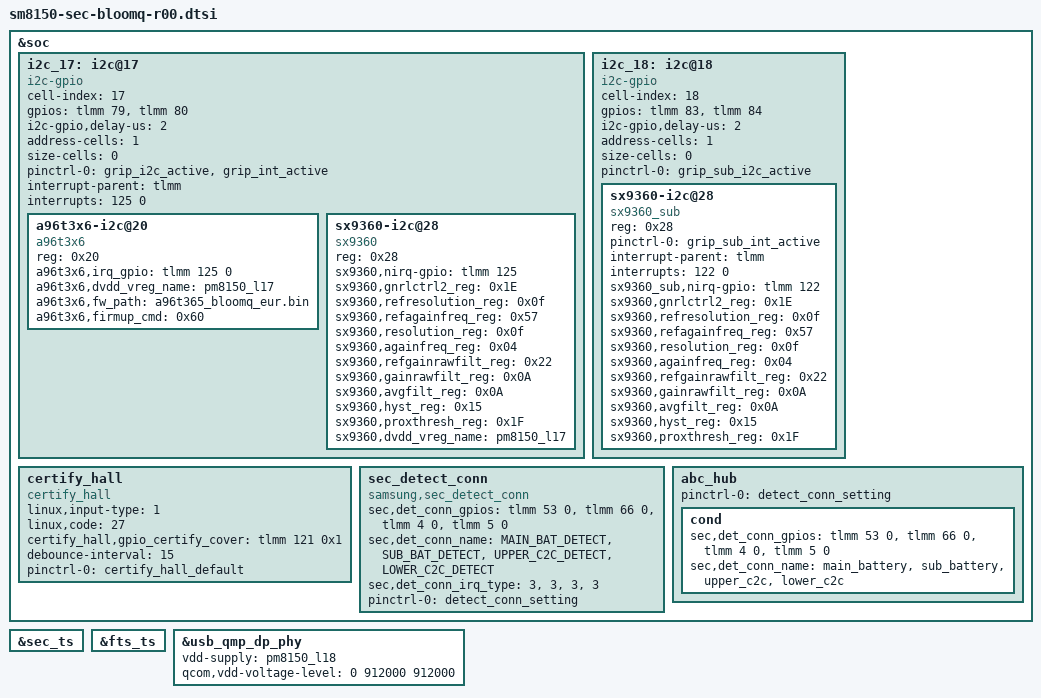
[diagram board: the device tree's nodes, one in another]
/* Copyright (c) 2016-2017, The Linux Foundation. All rights reserved.
 *
 * This program is free software; you can redistribute it and/or modify
 * it under the terms of the GNU General Public License version 2 and
 * only version 2 as published by the Free Software Foundation.
 *
 * This program is distributed in the hope that it will be useful,
 * but WITHOUT ANY WARRANTY; without even the implied warranty of
 * MERCHANTABILITY or FITNESS FOR A PARTICULAR PURPOSE.  See the
 * GNU General Public License for more details.
 */

#include "sm8150-sec-bloomq-common.dtsi"
#include "sm8150-sec-bloomq-optics-r00.dtsi"

&soc {
	i2c_17: i2c@17 { /* SW I2C */
		status = "ok";

		cell-index = <17>;
		compatible = "i2c-gpio";
		gpios = <&tlmm 79 0 /* sda */
			 &tlmm 80 0 /* scl */
		>;
		i2c-gpio,delay-us = <2>;
		address-cells = <1>;
		size-cells = <0>;
		pinctrl-names = "default";
		pinctrl-0 = <&grip_i2c_active &grip_int_active>;

		interrupt-parent = <&tlmm>;
		interrupts = <125 0>;

		a96t3x6-i2c@20 {
			compatible = "a96t3x6";
			reg = <0x20>;
			status = "okay";
			a96t3x6,irq_gpio = <&tlmm 125 0>;
			a96t3x6,dvdd_vreg_name = "pm8150_l17";
			a96t3x6,fw_path = "a96t365_bloomq_eur.bin";
			a96t3x6,firmup_cmd = <0x60>;
		};

		sx9360-i2c@28 {
			compatible = "sx9360";
			reg = <0x28>;
			status = "okay";
			sx9360,nirq-gpio = <&tlmm 125 0>;
			sx9360,gnrlctrl2_reg = <0x1E>; /* scanperiod */
			sx9360,refresolution_reg = <0x0f>; /* same as resolution_reg */
			sx9360,refagainfreq_reg = <0x57>; /* same as againfreq_reg */
			sx9360,resolution_reg = <0x0f>; /* resolution : 1024 */
			sx9360,againfreq_reg = <0x04>; /* freq : 125 kHz, again : +/-3.75 pF */
			sx9360,refgainrawfilt_reg = <0x22>; /* same as gainrawfilt_reg */
			sx9360,gainrawfilt_reg = <0x0A>; /* rawfilter : 1-1/4, gain : x1 */
			sx9360,avgfilt_reg = <0x0A>; /* avgnegfilt : 1-1/2, avgposfilt : 1-1/64 */
			sx9360,hyst_reg = <0x15>; /* hysteresis : +/-6 %, debouncer : 2 samples */
			sx9360,proxthresh_reg = <0x1F>; /* threshhold : 200 */
			/* this feature only for multiple grip support by one regulator (ABOV-1.6V / SETMECH-3.0V), Bloom temporary */
			sx9360,dvdd_vreg_name = "pm8150_l17";
		};
	};
	
	i2c_18: i2c@18 { /* SW I2C */
		status = "ok";

		cell-index = <18>;
		compatible = "i2c-gpio";
		gpios = <&tlmm 83 0 /* sda */
			 &tlmm 84 0 /* scl */
		>;
		i2c-gpio,delay-us = <2>;
		address-cells = <1>;
		size-cells = <0>;
		pinctrl-names = "default";
		pinctrl-0 = <&grip_sub_i2c_active>;

		sx9360-i2c@28 {
			compatible = "sx9360_sub";
			reg = <0x28>;
			status = "okay";
			pinctrl-names = "default";
			pinctrl-0 = <&grip_sub_int_active>;
			interrupt-parent = <&tlmm>;
			interrupts = <122 0>;

			sx9360_sub,nirq-gpio = <&tlmm 122 0>;
			sx9360,gnrlctrl2_reg = <0x1E>; /* scanperiod */
			sx9360,refresolution_reg = <0x0f>; /* same as resolution_reg */
			sx9360,refagainfreq_reg = <0x57>; /* same as againfreq_reg */
			sx9360,resolution_reg = <0x0f>; /* resolution : 1024 */
			sx9360,againfreq_reg = <0x04>; /* freq : 125 kHz, again : +/-3.75 pF */
			sx9360,refgainrawfilt_reg = <0x22>; /* same as gainrawfilt_reg */
			sx9360,gainrawfilt_reg = <0x0A>; /* rawfilter : 1-1/4, gain : x1 */
			sx9360,avgfilt_reg = <0x0A>; /* avgnegfilt : 1-1/2, avgposfilt : 1-1/64 */
			sx9360,hyst_reg = <0x15>; /* hysteresis : +/-6 %, debouncer : 2 samples */
			sx9360,proxthresh_reg = <0x1F>; /* threshhold : 200 */
		};
	};

        certify_hall {
                compatible = "certify_hall";
                linux,input-type = <1>;
                linux,code = <27>;
                certify_hall,gpio_certify_cover = <&tlmm 121 0x1>;
                debounce-interval = <15>;
		pinctrl-names = "default";
	        pinctrl-0 = <&certify_hall_default>;
        };

	sec_detect_conn {
		compatible = "samsung,sec_detect_conn";
		sec,det_conn_gpios = <&tlmm 53 0 /* MAIN_BAT_DETECT */
					&tlmm 66 0 /* SUB_BAT_DETECT */
					&tlmm 4 0 /* UPPER_C2C_DETECT */
					&tlmm 5 0>; /* LOWER_C2C_DETECT */

		sec,det_conn_name = "MAIN_BAT_DETECT", "SUB_BAT_DETECT", "UPPER_C2C_DETECT", "LOWER_C2C_DETECT";

		sec,det_conn_irq_type = <3>, /* MAIN_BAT_DETECT FALLING, RIGING EDGE*/
					<3>, /* SUB_BAT_DETECT FALLING, RIGING EDGE*/
					<3>, /* UPPER_C2C_DETECT FALLING, RIGING EDGE*/
					<3>; /* LOWER_C2C_DETECT FALLING, RIGING EDGE*/

		pinctrl-names = "det_ap_connect";
		pinctrl-0 = <&detect_conn_setting>;
	};

	abc_hub {
		pinctrl-names = "det_ap_connect";
		pinctrl-0 = <&detect_conn_setting>;


		cond {
			sec,det_conn_gpios = <&tlmm 53 0 /* MAIN_BAT_DETECT */
						&tlmm 66 0 /* SUB_BAT_DETECT */
						&tlmm 4 0 /* UPPER_C2C_DETECT */
						&tlmm 5 0>; /* LOWER_C2C_DETECT */
			sec,det_conn_name = "main_battery", "sub_battery", "upper_c2c", "lower_c2c";
		};
	};

};

&sec_ts {
	status = "ok";
};

&fts_ts {
	status = "ok";
};

&usb_qmp_dp_phy {
	vdd-supply = <&pm8150_l18>;
	qcom,vdd-voltage-level = <0 912000 912000>;
};
